# YTM32B1ME1 register map
Vendor: YTMicro; File version: 1.0
CPU: CM33 r0p4, little endian, MPU, FPU, 2 interrupt priority bits
Registers are 32-bit, read-write, reset 0x0 unless marked. A register's access mark holds for its fields unless they carry their own. Offsets are from the block's base; [hi:lo] are bit positions; {n}, {i} and the like mark numbered series.

## CIM — Chip Integration Module of Microcontroller
Base 0x401EC000; register names take the prefix CIM_
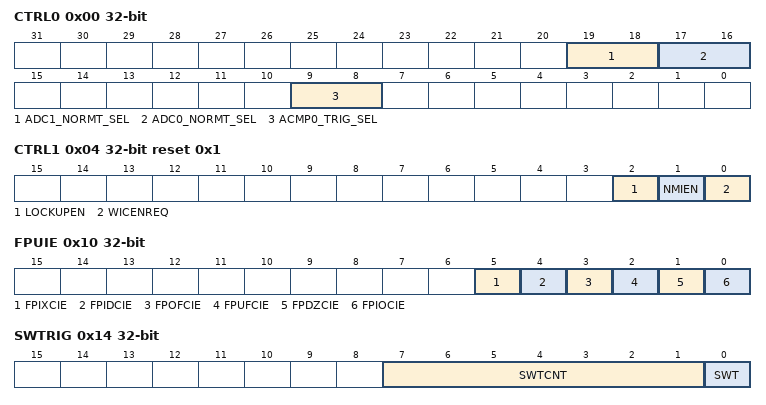
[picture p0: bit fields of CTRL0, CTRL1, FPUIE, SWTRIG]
0x00 CTRL0
  [19:18] ADC1_NORMT_SEL — Select trigger source for ADC1 normal mode.
    1=TMU output synced by bus clock; 2=TMU output synced by ADC1 func clock
  [17:16] ADC0_NORMT_SEL — Select trigger source for ADC0 Normal mode.
    1=TMU output synced by bus clock; 2=TMU output synced by ADC0 func clock
  [9:8] ACMP0_TRIG_SEL — ACMP0 Trigger Select
    0=TMU; 1=TMU synced by bus clock; 2=TMU synced by ACMP0 func clock
0x04 CTRL1 reset 0x1
  [2] LOCKUPEN — Enable CPU Lockup Reset
    0=CPU Lockup reset is disabled; 1=CPU Lockup reset is enabled
  [1] NMIEN — Enable NMI function
    0=NMI is disabled; 1=NMI is enabled
  [0] WICENREQ — Enable WIC to wakeup low power mode.
    0=Disable WIC to wakeup low power mode; 1=Enable WIC to wakeup low power mode
0x10 FPUIE
  [all] fields
    0=Disable interrupt; 1=Enable interrupt
  [5] FPIXCIE
  [4] FPIDCIE
  [3] FPOFCIE
  [2] FPUFCIE
  [1] FPDZCIE
  [0] FPIOCIE
0x14 SWTRIG
  [7:1] SWTCNT — Define software trigger valid length (multiplied with bus clock cycle), SWTCNT value will decrease until equal to zero when SWT set.
  [0] SWT — Generate software trigger.
    0=Software trigger is disabled; 1=Generate software trigger and it keeps until SWTCNT equals to zero
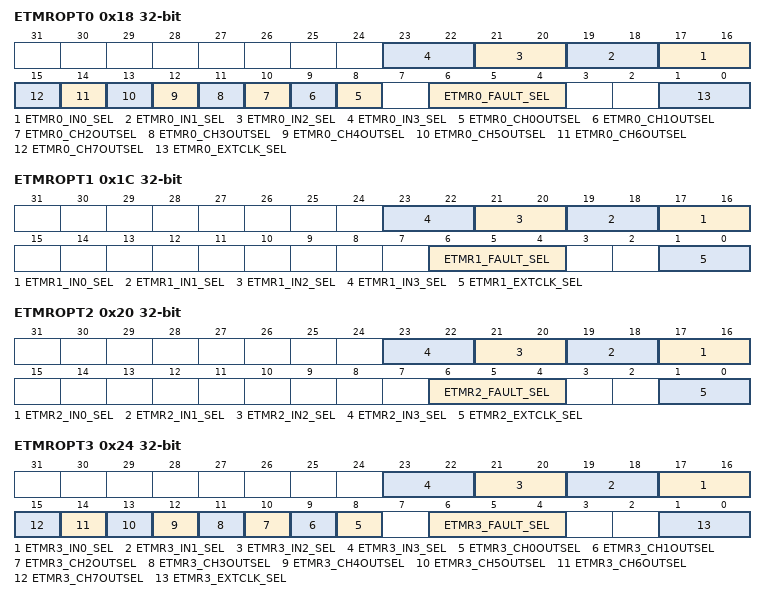
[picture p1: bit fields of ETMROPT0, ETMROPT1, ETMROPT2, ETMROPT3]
0x18 ETMROPT0
  [2n+17:2n+16] ETMR0_IN{n}_SEL (n=0..3) — Select eTMR0 channel{n} input sources.
    0=Select ETMR0_CH{n} input from pad; 1=Select TMU output; 2=Hall sensor XOR input (XOR of ETMR0_CH0/1/2)
  [n+8] ETMR0_CH{n}OUTSEL (n=0..7) — Select modulation with eTMR1_CH1 for eTMR0 channel {n}.
    0=eTMR0 channel {n} output to pad directly; 1=eTMR0 channel {n} output modulation with eTMR1_CH1 output
  [6:4] ETMR0_FAULT_SEL — Select fault source for eTMR0.
    0=eTMR0 fault 0 input from pad; 1=eTMR0 fault 0 input from TMU; 0=eTMR0 fault 1 input from pad; 2=eTMR0 fault 1 input from TMU; 0=eTMR0 fault 2 input from pad; 4=eTMR0 fault 2 input from TMU
  [1:0] ETMR0_EXTCLK_SEL — Select external clock source for eTMR0.
    0=Select TCLK_IN0 input as external clock for eTMR0; 1=Select TCLK_IN1 input as external clock for eTMR0; 2=Select TCLK_IN2 input as external clock for eTMR0; 3=Select ETMR0_FUNC_CLK from IPC as external clock for eTMR0
0x1C ETMROPT1
  [2n+17:2n+16] ETMR1_IN{n}_SEL (n=0..3) — Select eTMR1 channel{n} input sources.
    0=Select ETMR1_CH{n} input from pad; 1=Select TMU output; 2=Hall sensor XOR input (XOR of ETMR1_CH0/1/2)
  [6:4] ETMR1_FAULT_SEL — Select fault source for eTMR1.
    0=eTMR1 fault 0 input from pad; 1=eTMR1 fault 0 input from TMU; 0=eTMR1 fault 1 input from pad; 2=eTMR1 fault 1 input from TMU; 0=eTMR1 fault 2 input from pad; 4=eTMR1 fault 2 input from TMU
  [1:0] ETMR1_EXTCLK_SEL — Select external clock source for eTMR1.
    0=Select TCLK_IN0 input as external clock for eTMR1; 1=Select TCLK_IN1 input as external clock for eTMR1; 2=Select TCLK_IN2 input as external clock for eTMR1; 3=Select ETMR1_FUNC_CLK from IPC as external clock for eTMR1
0x20 ETMROPT2
  [2n+17:2n+16] ETMR2_IN{n}_SEL (n=0..3) — Select eTMR2 channel{n} input sources.
    0=Select ETMR2_CH{n} input from pad; 1=Select TMU output; 2=Hall sensor XOR input 1 (XOR of ETMR2_CH0/1/2); 3=Hall sensor XOR input 2 (XOR of ETMR2_CH0,ETMR2_CH1,ETMR1_CH1)
  [6:4] ETMR2_FAULT_SEL — Select fault source for eTMR2.
    0=eTMR2 fault 0 input from pad; 1=eTMR2 fault 0 input from TMU; 0=eTMR2 fault 1 input from pad; 2=eTMR2 fault 1 input from TMU; 0=eTMR2 fault 2 input from pad; 4=eTMR2 fault 2 input from TMU
  [1:0] ETMR2_EXTCLK_SEL — Select external clock source for eTMR2.
    0=Select TCLK_IN0 input as external clock for eTMR2; 1=Select TCLK_IN1 input as external clock for eTMR2; 2=Select TCLK_IN2 input as external clock for eTMR2; 3=Select ETMR2_FUNC_CLK from IPC as external clock for eTMR2
0x24 ETMROPT3
  [2n+17:2n+16] ETMR3_IN{n}_SEL (n=0..3) — Select eTMR3 channel{n} input sources.
    0=Select ETMR3_CH{n} input from pad; 1=Select TMU output; 2=Hall sensor XOR input (XOR of ETMR3_CH0/1/2)
  [n+8] ETMR3_CH{n}OUTSEL (n=0..7) — Select modulation with eTMR2_CH1 for eTMR3 channel {n}.
    0=eTMR3 channel {n} output to pad directly; 1=eTMR3 channel {n} output modulation with eTMR2_CH1 output
  [6:4] ETMR3_FAULT_SEL — Select fault source for eTMR3.
    0=eTMR3 fault 0 input from pad; 1=eTMR3 fault 0 input from TMU; 0=eTMR3 fault 1 input from pad; 2=eTMR3 fault 1 input from TMU; 0=eTMR3 fault 2 input from pad; 4=eTMR3 fault 2 input from TMU
  [1:0] ETMR3_EXTCLK_SEL — Select external clock source for eTMR3.
    0=Select TCLK_IN0 input as external clock for eTMR3; 1=Select TCLK_IN1 input as external clock for eTMR3; 2=Select TCLK_IN2 input as external clock for eTMR3; 3=Select ETMR3_FUNC_CLK from IPC as external clock for eTMR3
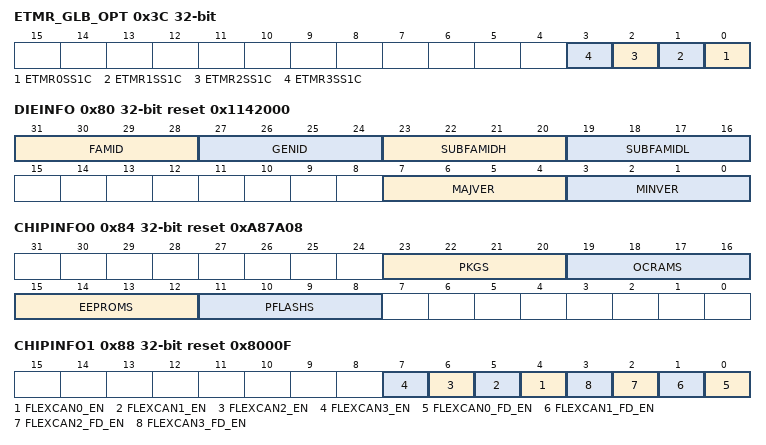
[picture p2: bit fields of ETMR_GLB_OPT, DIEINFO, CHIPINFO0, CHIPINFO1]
0x3C ETMR_GLB_OPT
  [n] ETMR{n}SS1C (n=0..3) — Generate synchronize signal for eTMR{n} trigger 1.
    0=Don't generate synchronize signal for eTMR{n} trigger 1; 1=Generate synchronize signal for eTMR{n} trigger 1
0x80 DIEINFO ro reset 0x1142000
  [31:28] FAMID — Describe the product family information.
    0=B - Basic(General); 1=D - Dashboard; 2=P - Powertrain; 3=V - Vision; 4=N - Networks
  [27:24] GENID — Describe the product generation information.
    1=1st generation production; 2=2nd generation production; 3=3rd generation production
  [23:20] SUBFAMIDH — Describe the product sub family information.
    0=L - Low end; 1=M - Middle end; 2=H - High end
  [19:16] SUBFAMIDL — Describe the product max Flash size information.
    0=A - 64KB; 1=B - 128KB; 2=C - 256KB; 3=D - 512KB; 4=E - 1MB
  [7:4] MAJVER — Describe the major version information.
  [3:0] MINVER — Describe the minor version information.
0x84 CHIPINFO0 ro reset 0xA87A08
  [23:20] PKGS — Describe chip package type information.
    0=16 TSOP; 1=32 LQFP; 2=32 QFN; 3=48 LQFP; 4=64 LQFP; 8=100 LQFP; 10=144 LQFP; 12=176 LQFP; 13=257 BGA; 15=289 BGA
  [19:16] OCRAMS — Describe ocram size information. This field indicates the size of OCRAML or OCRAMU. Total size is twice.
    2=1KB; 3=2KB; 4=4KB; 5=8KB; 6=16KB; 7=32KB; 8=64KB; 9=128KB; 10=256KB; 11=512KB; 12=1MB; 13=2MB; 14=4MB; 15=8MB
  [15:12] EEPROMS — Describe data flash size information.
    4=1KB; 5=2KB; 6=4KB; 7=8KB
  [11:8] PFLASHS — Describe program flash size information.
    0=1KB; 1=2KB; 2=4KB; 3=8KB; 4=16KB; 5=32KB; 6=64KB; 7=128KB; 8=256KB; 9=512KB; 10=1MB; 11=2MB; 12=4MB; 13=8MB; 14=16MB; 15=32MB
0x88 CHIPINFO1 ro reset 0x8000F
  [n+4] FLEXCAN{n}_EN (n=0..3) — FlexCAN{n} Enable/Disable
    0=FlexCAN{n} is disabled; 1=FlexCAN{n} is enabled
  [n] FLEXCAN{n}_FD_EN (n=0..3) — FlexCAN{n} FD Feature Enable/Disable
    0=FlexCAN{n} FD Feature is disabled; 1=FlexCAN{n} FD Feature is enabled
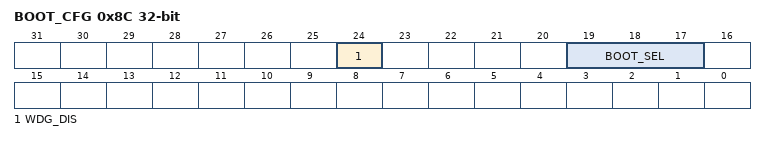
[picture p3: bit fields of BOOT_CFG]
0x8C BOOT_CFG ro
  [24] WDG_DIS rw — WDG disabled or not when chip boot
    0=WDG is default enabled; 1=WDG is default disable
  [19:17] BOOT_SEL rw — Select the base address chip boot from
    0=Flash base; 1=OCRAML base; 2=OCRAMU base; 3=ROM base; 5=NVR ROM base
